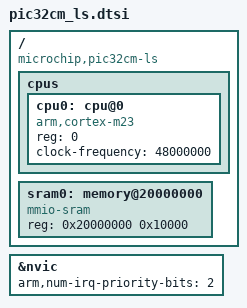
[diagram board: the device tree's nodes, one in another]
/*
 * Copyright (c) 2026
 *
 * SPDX-License-Identifier: Apache-2.0
 */

#include <arm/armv8-m.dtsi>

/ {
    compatible = "microchip,pic32cm-ls";

    cpus {
        #address-cells = <1>;
        #size-cells = <0>;

        cpu0: cpu@0 {
            device_type = "cpu";
            compatible = "arm,cortex-m23";
            reg = <0>;
            clock-frequency = <48000000>;
        };
    };

    sram0: memory@20000000 {
        compatible = "mmio-sram";
        reg = <0x20000000 0x10000>;
    };
};

&nvic {
    arm,num-irq-priority-bits = <2>;
};
